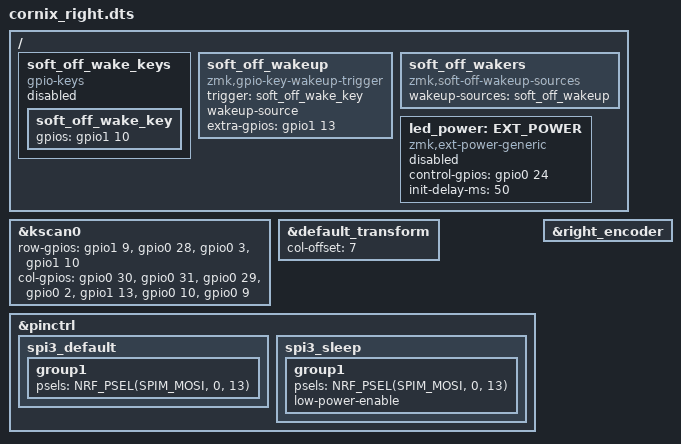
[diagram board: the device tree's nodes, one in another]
/*
 * Copyright (c) 2020 Pete Johanson
 *
 * SPDX-License-Identifier: MIT
 */
/dts-v1/;
#include "cornix.dtsi"

&kscan0 {
    // Right side has different row pins: [P1_09, P0_28, P0_03, P1_10]
    row-gpios
        = <&gpio1 9  (GPIO_ACTIVE_HIGH | GPIO_PULL_DOWN)>  // Row 0
        , <&gpio0 28 (GPIO_ACTIVE_HIGH | GPIO_PULL_DOWN)>  // Row 1
        , <&gpio0 3  (GPIO_ACTIVE_HIGH | GPIO_PULL_DOWN)>  // Row 2
        , <&gpio1 10 (GPIO_ACTIVE_HIGH | GPIO_PULL_DOWN)>  // Row 3
        ;

    // Right side column pins: [P0_30, P0_31, P0_29, P0_02, P1_13, P0_10, P0_09]
    col-gpios
        = <&gpio0 30 GPIO_ACTIVE_HIGH>  // Col 0
        , <&gpio0 31 GPIO_ACTIVE_HIGH>  // Col 1
        , <&gpio0 29 GPIO_ACTIVE_HIGH>  // Col 2
        , <&gpio0  2  GPIO_ACTIVE_HIGH> // Col 3
        , <&gpio1 13 GPIO_ACTIVE_HIGH>  // Col 4
        , <&gpio0 10 GPIO_ACTIVE_HIGH>  // Col 5
        , <&gpio0  9 GPIO_ACTIVE_HIGH>  // Col 6
        ;
};

&default_transform {
	col-offset = <7>;
};

// rgb,SPI
// see spi issue here https://github.com/zephyrproject-rtos/zephyr/issues/57147
&pinctrl {
    spi3_default: spi3_default {
        group1 {
            psels = <NRF_PSEL(SPIM_MOSI, 0, 13)>;
        };
    };

    spi3_sleep: spi3_sleep {
        group1 {
            psels = <NRF_PSEL(SPIM_MOSI, 0, 13)>;
            low-power-enable;
        };
    };
};


&right_encoder {
    status = "okay";
};

/ {
    soft_off_wake_keys {
        compatible = "gpio-keys";
        status = "disabled";

        soft_off_wake_key: soft_off_wake_key {
            gpios = <&gpio1 10 (GPIO_ACTIVE_HIGH | GPIO_PULL_DOWN)>;
        };
    };

    soft_off_wakeup: soft_off_wakeup {
        compatible = "zmk,gpio-key-wakeup-trigger";
        trigger = <&soft_off_wake_key>;
        wakeup-source;
        // Drive Col 4 so key position 45 (Row 3 x Col 4) wakes from soft off.
        // Must not be the off-combo key's column (46 = Row 3 x Col 3): the
        // peripheral powers off on combo press while that key is still held,
        // and an already-active SENSE line would wake it instantly.
        extra-gpios = <&gpio1 13 GPIO_ACTIVE_HIGH>;
    };

    soft_off_wakers {
        compatible = "zmk,soft-off-wakeup-sources";
        wakeup-sources = <&soft_off_wakeup>;
    };

    //hardcoding label for ext_power behavior
    led_power: EXT_POWER {
        status = "disabled";
        compatible = "zmk,ext-power-generic";
        control-gpios = <&gpio0 24 GPIO_ACTIVE_HIGH>;
        init-delay-ms = <50>;
    };
};

//vim: set ft=dts
